# TREMO register map
File version: 1.6.2
CPU: CM4 r0p1, little endian, MPU, FPU, 3 interrupt priority bits
Registers are 32-bit, read-write, reset 0x0 unless marked. A register's access mark holds for its fields unless they carry their own. Offsets are from the block's base; [hi:lo] are bit positions.

## EFC
Base 0x40020000
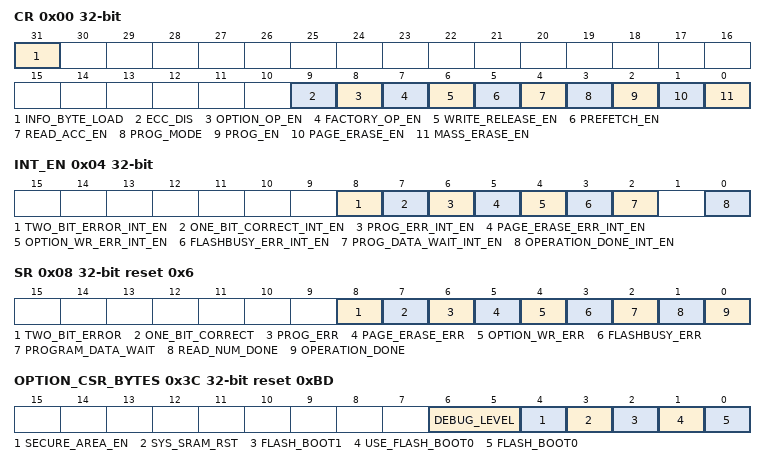
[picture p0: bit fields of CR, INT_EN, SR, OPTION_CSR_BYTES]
0x00 CR — control register
  [31] INFO_BYTE_LOAD — Info byte load reset request
  [9] ECC_DIS — ECC encoding disable
  [8] OPTION_OP_EN — Option operation enable
  [7] FACTORY_OP_EN
  [6] WRITE_RELEASE_EN
  [5] PREFETCH_EN — Flash instruction prefetch enable
  [4] READ_ACC_EN — Flash read acceleration enable
  [3] PROG_MODE — flash program mode selection
  [2] PROG_EN — Flash programming enable
  [1] PAGE_ERASE_EN — Flash page erasing enable
  [0] MASS_ERASE_EN — Flash mass erasing enable
0x04 INT_EN — interrupt enable register
  [8] TWO_BIT_ERROR_INT_EN — ECC TWO_BIT_ERROR interrupt enable
  [7] ONE_BIT_CORRECT_INT_EN — ECC ONE_BIT_CORRECT interrupt enable
  [6] PROG_ERR_INT_EN — PROG_ERR interrupt enable
  [5] PAGE_ERASE_ERR_INT_EN — PAGE_ERASE_ERR interrupt enable
  [4] OPTION_WR_ERR_INT_EN — OPTION_WR_ERR interrupt enable
  [3] FLASHBUSY_ERR_INT_EN — FLASHBUSY_ERR interrupt enable
  [2] PROG_DATA_WAIT_INT_EN — PROG_DATA_WAIT interrupt enable
  [0] OPERATION_DONE_INT_EN — OPERATION_DONE interrupt enable
0x08 SR reset 0x6 (reset mask 0x1F) — status register
  [8] TWO_BIT_ERROR — TWO_BIT_ERROR flag
  [7] ONE_BIT_CORRECT — ONE_BIT_CORRECT flag
  [6] PROG_ERR
  [5] PAGE_ERASE_ERR — The Flash info area don’t support erasing operation
  [4] OPTION_WR_ERR
  [3] FLASHBUSY_ERR
  [2] PROGRAM_DATA_WAIT — Waiting for data to be written to the Flash memory
  [1] READ_NUM_DONE ro — READ_NUM configuration status flag
  [0] OPERATION_DONE — Flash operation status flag
0x0C PROGRAM_DATA0
  [31:0] PROG_DATA0 — programming data 0
0x10 PROGRAM_DATA1
  [31:0] PROG_DATA1 — programming data 1
0x14 TIMING_CFG reset 0x31D1D — timing config register
  [19:16] READ_NUM — Program the number of wait states
0x18 PROTECT_SEQ wo — protect sequence register
  [31:0] PROTECT_SEQ — Protection sequence for the configuration of register EFC_CR
0x20 CHIP_PATTERN ro
0x24 IP_TRIM_L ro — analog ip trimming low register
  [31:0] TRIM
0x28 IP_TRIM_H ro — analog ip trimming high register
  [31:0] TRIM
0x2C SN_L ro — serial number low register
  [31:0] SERIAL_NUM_LOW — Less significant 32 bits of the chip serial number
0x30 SN_H ro — serial number high register
  [31:0] SERIAL_NUM_HIGH — More significant 32 bits of the chip serial number
0x34 TEST_INFO_L ro — test info low register
  [31:0] INFO
0x38 TEST_INFO_H ro — test info high register
  [31:0] INFO
0x3C OPTION_CSR_BYTES ro reset 0xBD — option control and status register
  [6:5] DEBUG_LEVEL — This bit can be used to identify the boot mode
  [4] SECURE_AREA_EN — Flash secure area status flag
  [3] SYS_SRAM_RST — Whether to clear system SRAM during system startup after its reset
  [2] FLASH_BOOT1 — This bit can be used to identify the boot mode
  [1] USE_FLASH_BOOT0 — This bit can be used to identify the boot mode
  [0] FLASH_BOOT0 — This bit can be used to identify the boot mode
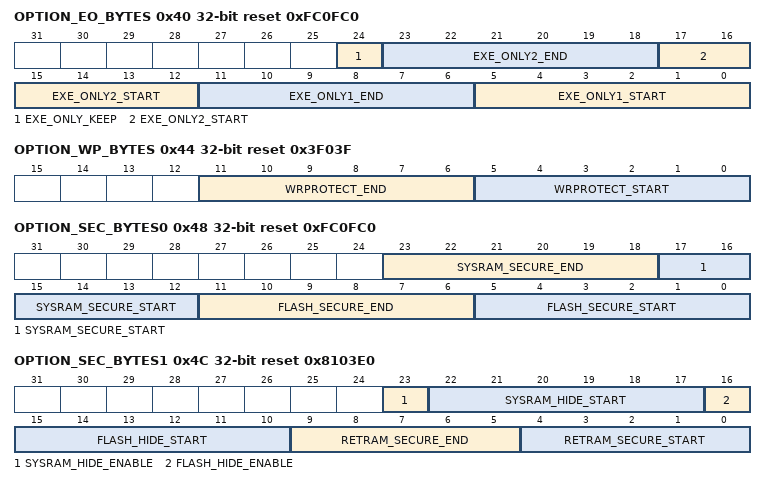
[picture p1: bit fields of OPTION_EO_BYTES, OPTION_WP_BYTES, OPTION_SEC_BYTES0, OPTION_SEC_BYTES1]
0x40 OPTION_EO_BYTES ro reset 0xFC0FC0 — option exe-only bytes register
  [24] EXE_ONLY_KEEP — Whether Exe_Only area is kept when the Debug_Level changes from 1 to 0
  [23:18] EXE_ONLY2_END — Exe_Only2 area end offset
  [17:12] EXE_ONLY2_START — Exe_Only2 area start offset
  [11:6] EXE_ONLY1_END — Exe_Only1 area end offset
  [5:0] EXE_ONLY1_START — Exe_Only1 area start offset
0x44 OPTION_WP_BYTES ro reset 0x3F03F — option write-protect bytes register
  [11:6] WRPROTECT_END — Write-protected area end offset
  [5:0] WRPROTECT_START — Write-protected area start offset
0x48 OPTION_SEC_BYTES0 ro reset 0xFC0FC0 — option secure byte 0 register
  [23:18] SYSRAM_SECURE_END — SysRam Secure area end
  [17:12] SYSRAM_SECURE_START — SysRam Secure area start
  [11:6] FLASH_SECURE_END — Flash Secure area end
  [5:0] FLASH_SECURE_START — Flash Secure area start
0x4C OPTION_SEC_BYTES1 ro reset 0x8103E0 — option secure byte 1 register
  [23] SYSRAM_HIDE_ENABLE — SysRamHide area enable control
  [22:17] SYSRAM_HIDE_START — SysRamHide area start
  [16] FLASH_HIDE_ENABLE — FlashHide area enable control
  [15:10] FLASH_HIDE_START — FlashHide area start
  [9:5] RETRAM_SECURE_END — RetRam Secure area end
  [4:0] RETRAM_SECURE_START — RetRam Secure area start
